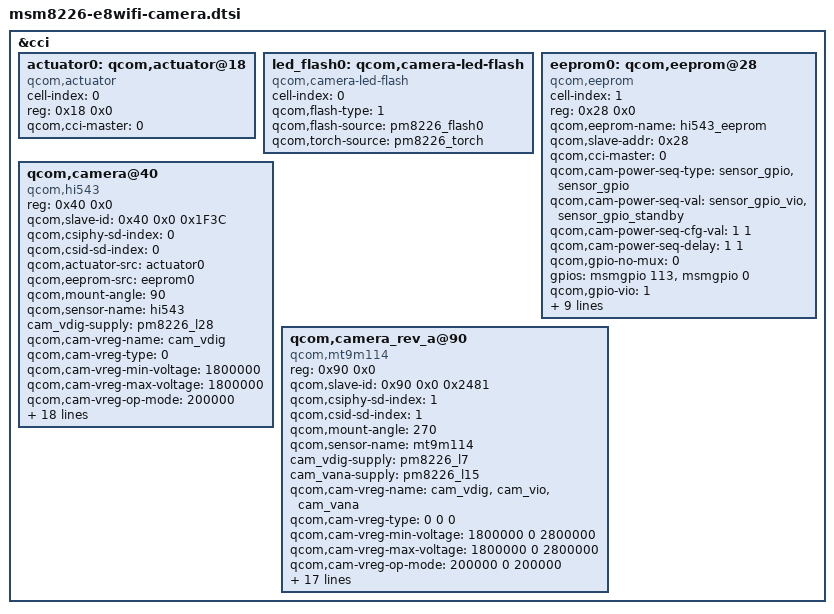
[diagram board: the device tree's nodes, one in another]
/*
 * Copyright (c) 2013, The Linux Foundation. All rights reserved.
 *
 * This program is free software; you can redistribute it and/or modify
 * it under the terms of the GNU General Public License version 2 and
 * only version 2 as published by the Free Software Foundation.
 *
 * This program is distributed in the hope that it will be useful,
 * but WITHOUT ANY WARRANTY; without even the implied warranty of
 * MERCHANTABILITY or FITNESS FOR A PARTICULAR PURPOSE.  See the
 * GNU General Public License for more details.
 */

&cci {
actuator0: qcom,actuator@18 {
	cell-index = <0>;	//Use Af_main_0 of dw9716 with HI543
	reg = <0x18 0x0>;
	compatible = "qcom,actuator";
	qcom,cci-master = <0>;
};

led_flash0: qcom,camera-led-flash {
	cell-index = <0>;
	compatible = "qcom,camera-led-flash";
	qcom,flash-type = <1>;
	qcom,flash-source = <&pm8226_flash0>;
        qcom,torch-source = <&pm8226_torch>;
};

eeprom0: qcom,eeprom@28 { //EEPROM READ
	cell-index = <1>;
	reg = <0x28 0x0>;
	qcom,eeprom-name = "hi543_eeprom";
	compatible = "qcom,eeprom";
	qcom,slave-addr = <0x28>;
	qcom,cci-master = <0>;

	qcom,cam-power-seq-type = "sensor_gpio","sensor_gpio";
	qcom,cam-power-seq-val = "sensor_gpio_vio","sensor_gpio_standby";
	qcom,cam-power-seq-cfg-val = <1 1>;
	qcom,cam-power-seq-delay = <1 1>;
	qcom,gpio-no-mux = <0>;
	gpios = <&msmgpio 113 0>,	//1.8V IOVDD
		<&msmgpio 0 0>;		//2.8V VCM
	qcom,gpio-vio = <1>;
	qcom,gpio-standby = <0>;		//CAM_STANDBY
	qcom,gpio-req-tbl-num = <0 1>;
	qcom,gpio-req-tbl-flags = <0 0>;
	qcom,gpio-req-tbl-label = "MAIN_VIO_EN","CAM_STANDBY";

	qcom,num-blocks = <1>;
	qcom,page0 = <0 0x0 1 0x0 1 20>; // valid size, addr, addr_t, data, data_t, delay
	qcom,poll0 = <0 0x0 1 0x0 1 20>;
	qcom,mem0  = <0x06 0x0000 2 0 1 0>; //EEPROM READ
};
	
	/* Rev A */
	qcom,camera@40 {
	compatible = "qcom,hi543";
	reg = <0x40 0x0>;
	qcom,slave-id = <0x40 0x0 0x1F3C>;
	qcom,csiphy-sd-index = <0>;
	qcom,csid-sd-index = <0>;
	qcom,actuator-src = <&actuator0>;
	//qcom,led-flash-src = <&led_flash0>;
	qcom,eeprom-src = <&eeprom0>;
	qcom,mount-angle = <90>;
	qcom,sensor-name = "hi543";
	cam_vdig-supply = <&pm8226_l28>;               // VREG_L28_CAM_DVDD_1V8 
	qcom,cam-vreg-name = "cam_vdig"; 
	qcom,cam-vreg-type = <0>; 
		qcom,cam-vreg-min-voltage = <1800000>;
		qcom,cam-vreg-max-voltage = <1800000>;
	qcom,cam-vreg-op-mode = <200000>;
	qcom,gpio-no-mux = <0>;
	gpios = <&msmgpio 26 0>,   // MAIN_CAM0_MCLK
		<&msmgpio 114 0>,  // MAIN_CAM0_RESET
		<&msmgpio 113 0>,  	// CAM_IOVDD_1V8 // MAIN_CAM_1V8_EN
		<&msmgpio 62 0>,   	// CAM_AVDD_2V8	// MAIN_CAM_2V8_EN
		<&msmgpio 0 0>;  	// CAM_VCM_2V8  // MAIN_CAM_AF_2V8_EN

	qcom,gpio-reset = <1>;
	qcom,gpio-vio = <2>;
	qcom,gpio-vana = <3>;
	qcom,gpio-vaf = <4>;
	qcom,gpio-req-tbl-num = <0 1 2 3 4>;
	qcom,gpio-req-tbl-flags = <1 0 0 0 0>;
	qcom,gpio-req-tbl-label = "MAIN_CAM0_MCLK",
		"MAIN_CAM0_RESET",
		"CAM_IOVDD_1V8",
		"CAM_AVDD_2V8",		
		"CAM_VCM_2V8";
	qcom,csi-lane-assign = <0x4320>;
	qcom,csi-lane-mask = <0x07>;
	qcom,sensor-position = <0>;
	qcom,sensor-mode = <0>;
	qcom,cci-master = <0>;
	revision = "rev_a...";
	status = "okay";
	};


	/* Rev A */
	qcom,camera_rev_a@90 {
	compatible = "qcom,mt9m114";
	reg = <0x90 0x0>;
	qcom,slave-id = <0x90 0x0 0x2481>;
	qcom,csiphy-sd-index = <1>;
	qcom,csid-sd-index = <1>;
	qcom,mount-angle = <270>;
	qcom,sensor-name = "mt9m114";
	cam_vdig-supply = <&pm8226_l7>;		// VREG_L7_1V8_VT_DVDD
	cam_vana-supply = <&pm8226_l15>;	// VREG_L15_2V85_VT_AVDD
	qcom,cam-vreg-name = "cam_vdig", "cam_vio", "cam_vana";
	qcom,cam-vreg-type = <0 0 0>;
	qcom,cam-vreg-min-voltage = <1800000 0 2800000>;
	qcom,cam-vreg-max-voltage = <1800000 0 2800000>;
	qcom,cam-vreg-op-mode = <200000 0 200000>;
	qcom,gpio-no-mux = <0>;
	gpios = <&msmgpio 27 0>,			//VT_CAM_MCLK
			<&msmgpio 28 0>,			//VT_CAM_RESET
			<&msmgpio 31 0>,		    //VT_1V8_VIO, VT_CAM_LDO_EN
			<&msmgpio 113 0>;  	// MAIN_CAM_VIO_1V8, LDO3_EN for I2c pullup
	qcom,gpio-reset = <1>;
	qcom,gpio-vio = <2>;
	qcom,gpio-vana = <3>;
	qcom,gpio-req-tbl-num = <0 1 2 3>;
	qcom,gpio-req-tbl-flags = <1 0 0 0>;
	qcom,gpio-req-tbl-label = "VT_CAM_MCLK",
			"CAM_RESET", "VT_CAM_IO",
		"MAIN_CAM_AVDD";
	qcom,csi-lane-assign = <0x4320>;
	qcom,csi-lane-mask = <0x3>;
	qcom,sensor-position = <1>;
	qcom,sensor-mode = <1>;
	qcom,cci-master = <0>;
	qcom,sensor-type = <1>;
	revision = "rev_a...";
	status = "okay";
	};

};
